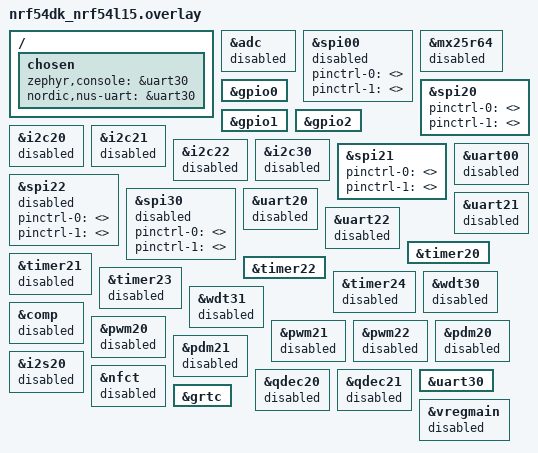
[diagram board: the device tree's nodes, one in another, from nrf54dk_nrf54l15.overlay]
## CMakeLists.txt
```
cmake_minimum_required(VERSION 3.20.0)
find_package(Zephyr REQUIRED HINTS $ENV{ZEPHYR_BASE})

project(ADC_2)

target_sources(app PRIVATE
  src/main.c
  src/BLE.c
  src/data.c
  src/rtc_stim.c
  src/spi.c
  src/timer.c
  src/ADC.c
)

if(CONFIG_BT)
  target_sources(app PRIVATE src/ble_session.c)
endif()
```

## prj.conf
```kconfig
#
# Copyright (c) 2024 Nordic Semiconductor
#
# SPDX-License-Identifier: LicenseRef-Nordic-5-Clause
#
CONFIG_BT=y
CONFIG_GPIO=y

#GATT
#CONFIG_BT_GATT_DYNAMIC_DB=names
CONFIG_BT_L2CAP_TX_BUF_COUNT=8
CONFIG_BT_BUF_ACL_TX_SIZE=251
CONFIG_BT_BUF_ACL_RX_SIZE=251
CONFIG_BT_CTLR_DATA_LENGTH_MAX=251
# STEP 1 - Enable nrfx drivers #
# Right names for low-level peripheral drivers
#CONFIG_ADC=y
CONFIG_NRFX_SAADC=y
CONFIG_NRFX_TIMER=y
CONFIG_NRFX_GPPI=y
# enable spi and other???
#CONFIG_CBPRINTF_FP_SUPPORT=y
#CONFIG_RESET_ON_FATAL_ERROR=n
#CONFIG_HEAP_MEM_POOL_SIZE=8192
#CONFIG_SYSTEM_WORKQUEUE_STACK_SIZE=2048
#CONFIG_MAIN_STACK_SIZE=4096
#CONFIG_THREAD_NAME=y
#CONFIG_BT_RX_STACK_SIZE=2048
# STEP 1.1 - Enable Kconfigs for SPI and GPIO
#CONFIG_GPIO=y
#CONFIG_SPI=y
##############################################################################
# BLE ON/OFF — set to n for RTC-only low-power stim (no radio)
##############################################################################

CONFIG_BT_PERIPHERAL=y
CONFIG_BT_DEVICE_NAME="Chronos"
CONFIG_BT_MAX_CONN=1
CONFIG_BT_NUS=y
#help buffers not to be dropped
CONFIG_BT_PERIPHERAL_PREF_MIN_INT=6
CONFIG_BT_PERIPHERAL_PREF_MAX_INT=6
CONFIG_BT_PERIPHERAL_PREF_LATENCY=0
CONFIG_BT_PERIPHERAL_PREF_TIMEOUT=400
#CONFIG_BT_NUS_SECURITY_ENABLED=n

##############################################################################
# Peripherals: GPIO, SPIM1, TIMER0 (burst), TIMER2 (period)
##############################################################################
#CONFIG_NRFX=y
CONFIG_DEVICE_DT_METADATA=n
CONFIG_DEVICE_DEPS=n
CONFIG_NRFX_SPIM=y
CONFIG_NRFX_TIMER=y
CONFIG_GPIO=y
#CONFIG_SPI=y
#CONFIG_NRFX_SPIM00=y
CONFIG_NRFX_QSPI=n
# TIMER: nRF54L15 uses TIMER20, TIMER22 etc. (enable per-instance in overlay if needed)
#CONFIG_NRFX_TIMER0=y
#CONFIG_NRFX_TIMER1=y

##############################################################################
# DK LEDs (BLE build uses dk_set_led in main)
##############################################################################
CONFIG_DK_LIBRARY=y

##############################################################################
# Heap / stacks (BLE needs more than RTC-only)
##############################################################################
CONFIG_HEAP_MEM_POOL_SIZE=8192
CONFIG_SYSTEM_WORKQUEUE_STACK_SIZE=2048
CONFIG_MAIN_STACK_SIZE=2048
CONFIG_BT_RX_STACK_SIZE=2048

##############################################################################
# UART / serial (NUS UART + console)
# NUS sample path expects async UART; enables CONFIG_BT_NUS_UART_* sizes in Kconfig.
##############################################################################
CONFIG_SERIAL=y
CONFIG_UART_ASYNC_API=y

##############################################################################
# Console / log / debug
##############################################################################
CONFIG_CONSOLE=y
CONFIG_UART_CONSOLE=y
CONFIG_PRINTK=y
CONFIG_USE_SEGGER_RTT=n
CONFIG_LOG=y
CONFIG_LOG_DEFAULT_LEVEL=2
CONFIG_DEBUG_THREAD_INFO=n
CONFIG_ASSERT=n

##############################################################################
# Boot / size
##############################################################################
CONFIG_BOOT_BANNER=n
CONFIG_NCS_BOOT_BANNER=n
CONFIG_SIZE_OPTIMIZATIONS=y

##############################################################################
# Flash
##############################################################################
CONFIG_FLASH=y
CONFIG_FLASH_MAP=n
CONFIG_FLASH_PAGE_LAYOUT=n
CONFIG_SPI_NOR=n
```

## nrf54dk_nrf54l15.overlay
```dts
&adc {
    status = "disabled";
};
/*
 * Copyright (c) 2024 Nordic Semiconductor ASA
 *
 * SPDX-License-Identifier: LicenseRef-Nordic-5-Clause
 */
/*
 * nRF54L15: SPIM20 on P1 (nrfx). SCK P1.05, MOSI P1.06, CS1 P1.09, CS2 P1.14.
 * UART20 disabled so P1.x available. nrfx configures GPIO+PSEL; no pinctrl for SPI.
 */

/* Disabled: nrfx uses SPIM21; keep mx25r64 disabled to avoid spi00 bus reference. */
&spi00 {
	status = "disabled";
	pinctrl-0 = <>;
	pinctrl-1 = <>;
	pinctrl-names = "default", "sleep";
};
&mx25r64 {
	status = "disabled";
};
/* status = "okay" so SoC domain/clock for SPIM20 is enabled; nrfx drives SPI, no Zephyr SPI driver. */
&spi20 {
	status = "okay";
	pinctrl-0 = <>;
	pinctrl-1 = <>;
	pinctrl-names = "default", "sleep";
};

/* Still need to release NFC pins for GPIO use */
&gpio0 {
	status = "okay";
};
&gpio1 {
	status = "okay";
};
&gpio2 {
	status = "okay";
};
/* MBOX (IPC hardware) must be okay for BLE-over-IPC; fixes __device_dts_ord_25 undeclared. */
//&mbox {
	//status = "okay";
//};

/*
 * Power: explicitly disable unused peripherals so they are not initialized
 * (no clocks, no power to those blocks). App uses: uart30, spi20 (nrfx SPIM20), timer00/10 (nrfx), gpio, flash, mbox.
 * nRF54L15 labels: i2c20/21/22/30, spi00/20/21/22/30, uart00/20/21/22/30, timer20/21/22/23/24, etc.
 */
&i2c20 { status = "disabled"; };
&i2c21 { status = "disabled"; };
&i2c22 { status = "disabled"; };
&i2c30 { status = "disabled"; };
/* spi00/spi20 cleared above for nrfx; clear pinctrl on rest to avoid device ord refs. */
&spi21 {
	status = "okay";
	pinctrl-0 = <>;
	pinctrl-1 = <>;
	pinctrl-names = "default", "sleep";
};
&spi22 {
	status = "disabled";
	pinctrl-0 = <>;
	pinctrl-1 = <>;
	pinctrl-names = "default", "sleep";
};
&spi30 {
	status = "disabled";
	pinctrl-0 = <>;
	pinctrl-1 = <>;
	pinctrl-names = "default", "sleep";
};
&uart00 { status = "disabled"; };
&uart20 { status = "disabled"; };
&uart21 { status = "disabled"; };
&uart22 { status = "disabled"; };
&adc { status = "disabled"; };
&timer20 { status = "okay"; };
&timer21 { status = "disabled"; };
&timer22 { status = "okay"; };
&timer23 { status = "disabled"; };
&timer24 { status = "disabled"; };
&wdt30 { status = "disabled"; };
&wdt31 { status = "disabled"; };
&comp { status = "disabled"; };
&pwm20 { status = "disabled"; };
&pwm21 { status = "disabled"; };
&pwm22 { status = "disabled"; };
&pdm20 { status = "disabled"; };
&pdm21 { status = "disabled"; };
&i2s20 { status = "disabled"; };
&nfct { status = "disabled"; };
&qdec20 { status = "disabled"; };
&qdec21 { status = "disabled"; };

/* LFXO: reverted - disabling it increased power on this design. Leave default. */
/* &lfxo { status = "disabled"; }; */
/ {
	chosen {
		zephyr,console = &uart30;
		nordic,nus-uart = &uart30;
	};
};

/* nRF54L15 DK uses UART30 for NUS; ensure it is enabled. */
&uart30 {
	status = "okay";
};
&grtc {
    status = "okay";
};
&vregmain {
    status = "disabled";
};
```

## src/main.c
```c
/*
Author: Brandon S Coventry      Wisconsin Institute for Translational Neuroengineering
Date: 2026/02/12 Initialization
Purpose: Chronos firmware ported for the nRF54L15
Revision History: See Github history
Notes:
 - Includes the ability to turn bluetooth transmission on and off in config file. Set CONFIG_BT in config file to 0 to turn off BLE engine
 - Primary stimulation driver is still and interupt based routine. 
*/

/*Basic includes. Minimize to limit current draw from unused engines.*/
//Zephyr includes
#include <zephyr/kernel.h>
#include <zephyr/types.h>
#include <zephyr/irq.h> //Interrupt service routine handlers
#include <zephyr/device.h>  //Must import devicetree files
#include <zephyr/devicetree.h>
#include <soc.h>    //Standard System on chip imports
#include <zephyr/logging/log.h>   //Disable on compile
#include <inttypes.h>

#if defined(CONFIG_BT)
#include <zephyr/bluetooth/bluetooth.h>
#include <zephyr/bluetooth/conn.h>
#endif

//nRFX imports. Note we are primarily runnig
#include <nrfx_spim.h>
#include <nrfx_timer.h>
#include <zephyr/sys/atomic.h>
#include <hal/nrf_gpio.h>
#include <hal/nrf_clock.h>
#if defined(CONFIG_NRFX_SAADC)
#include <nrfx_saadc.h>
#include <helpers/nrfx_gppi.h>
#endif
#if defined(CONFIG_SPI)
#include <zephyr/drivers/spi.h>
#endif

//Chronos engine imports 
#include "BLE.h"  //BLE engine
#include "ble_session.h"
#include "spi.h" //SPI to howland current source
#include "timer.h"  //Handles interrupt timing of stimulation
#include "rtc_stim.h"   //handles IRQ routines for stimulation
#include "data.h"
#include "config.h"   //Set compilation settings. Look here for CONFIG_BT
#include "ADC.h"

#define LOG_MODULE_NAME main
LOG_MODULE_REGISTER(LOG_MODULE_NAME, LOG_LEVEL_INF);

//Add UART Driver only if BLE is active. Note, UART is *virtual*, but still requires pin definitions. 
#if defined(CONFIG_BT)
#include <uart_async_adapter.h>
#include <zephyr/drivers/uart.h>
#include <zephyr/usb/usb_device.h>
#endif

//Set up peripherial initialization
static void init_clock();   //Turn on stimulation timing engine
#if defined(CONFIG_BT)
BT_CONN_CB_DEFINE(conn_callbacks) = {
	.connected        = connected,
	.disconnected     = disconnected,
	.recycled         = recycled_cb,
#ifdef CONFIG_BT_NUS_SECURITY_ENABLED
	.security_changed = security_changed,
#endif
};
#endif /* CONFIG_BT */

static void init_pins(void) {
    /* SPI CS and switches are GPIO. When CONFIG_SPI=y the Zephyr driver owns DAC1_CS (P1.08 in Zephyr devicetree). */
#if !defined(CONFIG_SPI)
    nrf_gpio_cfg_output(DAC1_CS_PIN);
    nrf_gpio_pin_set(DAC1_CS_PIN);   /* high (inactive) */
#endif
    nrf_gpio_cfg_output(DAC2_CS_PIN);
    nrf_gpio_pin_set(DAC2_CS_PIN);   /* high (inactive) */
    
    // Switch GPIOs (DAC1/2 -> switch): all 0 at init (merged 0.02/0.03 line)
    nrf_gpio_cfg_output(NRF_GPIO_PIN_MAP(1, 13));
    nrf_gpio_pin_clear(NRF_GPIO_PIN_MAP(1, 13));
    nrf_gpio_cfg_output(NRF_GPIO_PIN_MAP(1, 7));
    nrf_gpio_pin_clear(NRF_GPIO_PIN_MAP(1, 7));
    nrf_gpio_cfg_output(NRF_GPIO_PIN_MAP(1, 5));
    nrf_gpio_pin_clear(NRF_GPIO_PIN_MAP(1, 5));
}

int main(void)
{
    //Begin with system initialization




#if defined(CONFIG_BT)
    init_clock();
#endif
    init_pins();
#if defined(CONFIG_SPI)
    /* Zephyr SPI test build: no nrfx SPI/timer activity here. */
    k_msleep(10);
#else
    /* nrfx build: initialize SPI once; transactions are driven from timer ISR. */
    spi_init();
#endif
#if defined(CONFIG_BT)
    timer_init();
#else
    timer_burst_init();
#endif
    update_pulse_width(CONFIG_PULSE_WIDTH_US);
    update_dac1_amplitude(CONFIG_STIM_AMPLITUDE);
    update_dac2_amplitude(CONFIG_STIM_AMPLITUDE);

    data_init_defaults();

#if defined(CONFIG_BT)
	/* Stimulation timer stays off until START control byte (see data.c). */
	measurement_timer_init();
	int err = 0;
	uint32_t experiment_counter = 0;

	configure_gpio();
	err = uart_init();
	if (err) {
		error();
	}

	if (IS_ENABLED(CONFIG_BT_NUS_SECURITY_ENABLED)) {
		err = bt_conn_auth_cb_register(&conn_auth_callbacks);
		if (err) {
			LOG_ERR("Failed to register authorization callbacks. (err: %d)", err);
			return 0;
		}

		err = bt_conn_auth_info_cb_register(&conn_auth_info_callbacks);
		if (err) {
			LOG_ERR("Failed to register authorization info callbacks. (err: %d)", err);
			return 0;
		}
	}

	ble_session_init();
	LOG_INF("Toggle reed P1.10 to enable BLE; stimulation off until START byte");


	/* RUN_STATUS_LED is driven by ble_session (on while BLE session active). */
	for (;;) {
		if (MEASURE_TIMER == 1) {
			k_msleep(10000);
			experiment_counter += 10;
			error_data my_error_data;
			get_error_data(&my_error_data);
			printf("Counter: %i Elapsed: %is\nEvent0 running error: %" PRIu32
			       " avg error: %" PRIu32 " max error: %" PRIu32 "\n"
			       "Events1-3 running error: %" PRIu32 " avg error: %" PRIu32
			       " max error: %" PRIu32 ", %" PRIu32 ", %" PRIu32 "\n",
			       my_error_data.mycounter,
			       experiment_counter,
			       my_error_data.event0_error,
			       (my_error_data.event0_error / my_error_data.mycounter),
			       my_error_data.event0_max,
			       my_error_data.myerror,
			       (my_error_data.myerror / my_error_data.mycounter),
			       my_error_data.event1_max,
			       my_error_data.event2_max,
			       my_error_data.event3_max);
		} else {
			k_sleep(K_FOREVER);
		}
	}
    #else
        /* RTC low-power: no BLE; RTC wakes every stim period, timer runs one biphasic burst */
        rtc_stim_start_lfclk();
        rtc_stim_init(CONFIG_STIM_FREQUENCY_HZ);
        LOG_INF("RTC-driven stimulation at %u Hz (no BLE)", CONFIG_STIM_FREQUENCY_HZ);
        for (;;) {
            k_sleep(K_FOREVER);
        }
    #endif /* CONFIG_BT */


    }

    K_THREAD_DEFINE(ble_write_thread_id, STACKSIZE, ble_write_thread, NULL, NULL,
            NULL, PRIORITY, 0, 0);

    static void init_clock() {
#if !defined(CONFIG_SOC_NRF54L15)
        nrf_clock_hfclk_src_set(NRF_CLOCK_S, NRF_CLOCK_HFCLK_HIGH_ACCURACY);
#endif
        nrf_clock_task_trigger(NRF_CLOCK_S, NRF_CLOCK_TASK_HFCLKSTART);
        while (!nrf_clock_event_check(NRF_CLOCK_S, NRF_CLOCK_EVENT_HFCLKSTARTED)) {
            /* spin */
        }
        nrf_clock_event_clear(NRF_CLOCK_S, NRF_CLOCK_EVENT_HFCLKSTARTED);
    }
```

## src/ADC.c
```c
#include <zephyr/kernel.h>
#include <zephyr/logging/log.h>

LOG_MODULE_REGISTER(Chronos_adc, LOG_LEVEL_DBG);

/* STEP 2 - Include header for nrfx drivers */
#include <nrfx_saadc.h>
#include <nrfx_timer.h>
#include <helpers/nrfx_gppi.h>
// Include headers for zephyr SPI driver//
#include <zephyr/logging/log.h>
#include <zephyr/device.h>
#include <zephyr/devicetree.h>
#include <zephyr/drivers/gpio.h>
#include "BLE.h"
#include "ADC.h"





//#define SAADC_INPUT_PIN2 NRFX_ANALOG_EXTERNAL_AIN2
static nrfx_saadc_channel_t channel1 = NRFX_SAADC_DEFAULT_CHANNEL_SE(SAADC_INPUT_PIN1, 0);
//static nrfx_saadc_channel_t channel2 = NRFX_SAADC_DEFAULT_CHANNEL_SE(SAADC_INPUT_PIN2, 0);
//Define the SPI INIT
//SPI worc set changed to 16, see what happens, change back to 8 if not helpful
/* STEP 3.2 - Declaring an instance of nrfx_timer for TIMER2. */
nrfx_timer_t timer_instance = NRFX_TIMER_INSTANCE(TIMER_INSTANCE_NUMBER);
//New added up here hmmmmmm lets see
/* STEP 4.2 - Declare the buffers for the SAADC */
static int16_t saadc_sample_buffer[8][SAADC_BUFFER_SIZE];
//establishing a message queue for SAADC filled buffer pointers
K_MSGQ_DEFINE(ble_msgq, sizeof(int16_t *), 8, 4);
//Begins the spi thread of communication//
static void ble_thread(void *a, void *b, void *c) {
    k_sem_take(&ble_init_ok, K_FOREVER);
    int16_t *buf;
    while (1) {
        k_msgq_get(&ble_msgq, &buf, K_FOREVER);
        if (!current_conn) {
            continue;
        }
        ble_send_samples(buf, SAADC_BUFFER_SIZE);
        LOG_INF("Sample sent succesfully!");
    }
}
K_THREAD_DEFINE(ble_tid, 4096, ble_thread, NULL, NULL, NULL, 3, 0, 0);

/* STEP 4.3 - Declare variable used to keep track of which buffer was last assigned to the SAADC driver */
static uint32_t saadc_current_buffer = 2;

/*functions to control adc recording and stopping*/
static bool adc_active = false;
bool adc_recording_is_active(void) {
    return adc_active;
}
void adc_recording_start(void) {
    if (adc_active) {
        LOG_INF("SAADC already running");
        return;
    }
    configure_timer();
    configure_saadc();
    configure_ppi();
    adc_active=true;
    LOG_INF("SAADC recording started");
}
void adc_recording_stop(void) {
    if (!adc_active) {
        LOG_INF("SAADC already stopped");
        return;
    }
    nrfx_timer_disable(&timer_instance);
    nrfx_timer_uninit(&timer_instance);
    nrfx_saadc_uninit();
    saadc_current_buffer = 2;
    adc_active = false;
    LOG_INF("SAADC recording stopped");
}


void configure_timer(void)
{
    nrfx_err_t err;

    /* STEP 3.3 - Declaring timer config and intialize nrfx_timer instance. */
    nrfx_timer_config_t timer_config = NRFX_TIMER_DEFAULT_CONFIG(1000000);
    err = nrfx_timer_init(&timer_instance, &timer_config, NULL);
    if (err !=0) {
        LOG_ERR("nrfx_timer_init error: %08x", err);
        return;
    }

    /* STEP 3.4 - Set compare channel 0 to generate event every SAADC_SAMPLE_INTERVAL_US. */
    uint32_t timer_ticks = nrfx_timer_us_to_ticks(&timer_instance, SAADC_SAMPLE_INTERVAL_US);
    nrfx_timer_extended_compare(&timer_instance, NRF_TIMER_CC_CHANNEL0, timer_ticks, NRF_TIMER_SHORT_COMPARE0_CLEAR_MASK, false);
    LOG_INF("nrfx timer22 configured successfully");

}

static void saadc_event_handler(nrfx_saadc_evt_t const * p_event)
{
    nrfx_err_t err;
    switch (p_event->type)
    {

        case NRFX_SAADC_EVT_READY:
        
           /* STEP 5.1 - Buffer is ready, timer (and sampling) can be started. */
           nrfx_timer_enable(&timer_instance);

            break;                        
            
       case NRFX_SAADC_EVT_BUF_REQ:
        uint32_t next = saadc_current_buffer % 8;
           err = nrfx_saadc_buffer_set(saadc_sample_buffer[next], SAADC_BUFFER_SIZE);
            if (err != 0) {
            LOG_ERR("nrfx_saadc_buffer_set error: %08x  init", err);
            return;
            }
            saadc_current_buffer++;
            break;
         //   uint32_t next = saadc_current_buffer % 4;
           // err = nrfx_saadc_buffer_set(saadc_sample_buffer[next], SAADC_BUFFER_SIZE);
            //if (err != 0) {
            //LOG_ERR("nrfx_saadc_buffer_set error: %08x", err);
            //return;
            //}
            //saadc_current_buffer++;
        
            /* STEP 5.2 - Set up the next available buffer. Alternate through buffers 0-4 */
           
            

           // err = nrfx_saadc_buffer_set(saadc_sample_buffer[(saadc_current_buffer++)%4], SAADC_BUFFER_SIZE);
            //if (err != 0) {
              //  LOG_ERR("nrfx_saadc_buffer_set error: %08x", err);
                //return;
            //}

            //break;

        case NRFX_SAADC_EVT_DONE:
           

           // err = nrfx_saadc_buffer_set(saadc_sample_buffer[next], SAADC_BUFFER_SIZE);
            //if (err != 0) {
            //LOG_ERR("nrfx_saadc_buffer_set error: %08x init", err);
            //return;
            //}
           // saadc_current_buffer++;
         /* STEP 5.3 - Buffer has been filled. Do something with the data and proceed */
          /*  int64_t average = 0;
            int16_t max = INT16_MIN;
            int16_t min = INT16_MAX;
            int16_t current_value; 
            for(int i=0; i < p_event->data.done.size; i++){
                current_value = ((int16_t *)(p_event->data.done.p_buffer))[i];
                average += current_value;
                if(current_value > max){
                    max = current_value;
                }
                if(current_value < min){
                    min = current_value;
                }
            }
            average = average/p_event->data.done.size;
            LOG_INF("SAADC buffer at 0x%x filled with %d samples", (uint32_t)p_event->data.done.p_buffer, p_event->data.done.size);
            LOG_INF("AVG=%d, MIN=%d, MAX=%d", (int16_t)average, min, max);
            break;*/
        //default:
          //  LOG_INF("Unhandled SAADC evt %d", p_event->type);
           // break;

            /* STEP 5.3 - Buffer has been filled. Do something with the data and proceed */ //This will be changed to instead pass the buffer through SPI to fRAM//

         //  { int16_t *buf   = ((int16_t *)(p_event->data.done.p_buffer));
           // uint16_t count = (p_event->data.done.size);   /* number of int16_t samples */

           //  spi_send_samples(buf, count);

                /* Re-arm the same buffer for the next fill */
           // }
           //puts message of filled buffer pointer into queue
           int16_t *buf = p_event->data.done.p_buffer;
           int ret = k_msgq_put(&ble_msgq, &buf, K_NO_WAIT);
            if (ret != 0) {
            LOG_ERR("BLE msgq full! Buffer dropped at 0x%x", (uint32_t)buf);
            }
            

            break;
             default:
            LOG_INF("Unhandled SAADC evt %d", p_event->type);
            break;
        }     
       

}


void configure_saadc(void)
{
    nrfx_err_t err;

    /* STEP 4.4 - Connect ADC interrupt to nrfx interrupt handler */
    IRQ_CONNECT(DT_IRQN(DT_NODELABEL(adc)),
              DT_IRQ(DT_NODELABEL(adc), priority),
            nrfx_isr, nrfx_saadc_irq_handler, 0);
    /* STEP 4.5 - Initialize the nrfx_SAADC driver */
    err = nrfx_saadc_init(DT_IRQ(DT_NODELABEL(adc), priority));
    if (err!= 0) {
        LOG_ERR("nrfx_saadc_init error: %08x", err);
        return;
    }

    /* STEP 4.7 - Change gain config in default config and apply channel configuration */
    channel1.channel_config.gain = NRF_SAADC_GAIN1_4;
    channel1.channel_config.reference= NRF_SAADC_REFERENCE_INTERNAL;
    err = nrfx_saadc_channels_config(&channel1, 1);
    if (err != 0) {
        LOG_ERR("nrfx_saadc_channels_config error : %08x", err);
        return;
    }
    //channel2.channel_config.gain = NRF_SAADC_GAIN1_4;
    //channel2.channel_config.reference= NRF_SAADC_REFERENCE_INTERNAL;
    //err = nrfx_saadc_channels_config(&channel2, 1);
    //if (err != 0) {
      //  LOG_ERR("nrfx_saadc_channels_config error : %08x",err);
        //return;
    //}

    /* STEP 4.8 - Configure channel 0 in advanced mode with event handler (non-blocking mode) */

    nrfx_saadc_adv_config_t saadc_adv_config = NRFX_SAADC_DEFAULT_ADV_CONFIG;
    err = nrfx_saadc_advanced_mode_set(BIT(0),
                                        NRF_SAADC_RESOLUTION_12BIT,
                                        &saadc_adv_config,
                                        saadc_event_handler);
    if (err != 0) {
        LOG_ERR("nrfx_saadc_advanced_mode_set error: %08x", err);
        return;
    }

    /* STEP 4.9 - Configure two buffers to make use of double-buffering feature of SAADC */
    err = nrfx_saadc_buffer_set(saadc_sample_buffer[0], SAADC_BUFFER_SIZE);
    if (err != 0) {
        LOG_ERR("nrfx_saadc_buffer_set error: %08x 1", err);
        return;
    }
    err = nrfx_saadc_buffer_set(saadc_sample_buffer[1], SAADC_BUFFER_SIZE);
    if (err != 0) {
        LOG_ERR("nrfx_saadc_buffer_set error: %08x 2", err);
        return;
        LOG_INF("nrfx saadc configured successfully");
    }
   // err = nrfx_saadc_buffer_set(saadc_sample_buffer[2], SAADC_BUFFER_SIZE);
    //if (err != 0) {
      //  LOG_ERR("nrfx_saadc_buffer_set error: %08x 3", err);
        //return;
    //}
    //err = nrfx_saadc_buffer_set(saadc_sample_buffer[3], SAADC_BUFFER_SIZE);
    //if (err != 0) {
      //  LOG_ERR("nrfx_saadc_buffer_set error: %08x 4", err);
        //return;
    //}

    /* STEP 4.10 - Trigger the SAADC. This will not start sampling, but will prepare buffer for sampling triggered through PPI */
    err = nrfx_saadc_mode_trigger();
    if (err != 0) {
        LOG_ERR("nrfx_saadc_mode_trigger error: %08x", err);
        return;
    }

}

void configure_ppi(void)
{
    nrfx_err_t err;
    /* STEP 6.1 - Declare variables used to hold the (D)PPI channel number */
    nrfx_gppi_handle_t gppi_handle_sample;
    nrfx_gppi_handle_t gppi_handle_start;

    /* STEP 6.2 - Trigger task sample from timer */
    err = nrfx_gppi_conn_alloc( nrfx_timer_compare_event_address_get(&timer_instance, NRF_TIMER_CC_CHANNEL0),
                                nrf_saadc_task_address_get(NRF_SAADC, NRF_SAADC_TASK_SAMPLE), &gppi_handle_sample);
       if (err != 0) {
        LOG_ERR("nrfx_gppi_conn_alloc error: %08x", err);
        return;
       }                        
    /* STEP 6.3 - Trigger task start from end event */
    err = nrfx_gppi_conn_alloc(nrf_saadc_event_address_get(NRF_SAADC, NRF_SAADC_EVENT_END),
                                nrf_saadc_task_address_get(NRF_SAADC, NRF_SAADC_TASK_START), &gppi_handle_start);
    if (err != 0) {
        LOG_ERR("nrfx_gppi_conn_alloc error: %08x", err);
        return;
    } 
    /* STEP 6.4 - Enable both (D)PPI channels */ 
    nrfx_gppi_conn_enable(gppi_handle_sample);
nrfx_gppi_conn_enable(gppi_handle_start);
}
```

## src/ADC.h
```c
#ifndef ADC_H
#define ADC_H
#endif
#include <zephyr/device.h>
#include <zephyr/devicetree.h>
#include <zephyr/kernel.h>

#if defined(CONFIG_NRFX_SAADC)
#include <nrfx_saadc.h>
#endif
#define SAADC_SAMPLE_INTERVAL_US 500
#define SAADC_BUFFER_SIZE 8
#define SAADC_INPUT_PIN1 NRFX_ANALOG_EXTERNAL_AIN5
#define TIMER_INSTANCE_NUMBER NRF_TIMER22
void configure_timer(void);
void configure_saadc(void);
void configure_ppi(void);
void adc_recording_start(void);
void adc_recording_stop(void);
bool adc_recording_is_active(void);
```

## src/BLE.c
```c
#if defined(CONFIG_BT)
#include <uart_async_adapter.h>
#include <zephyr/drivers/uart.h>
#include <zephyr/usb/usb_device.h>
#include <dk_buttons_and_leds.h>
#endif

#include <zephyr/types.h>
#include <zephyr/kernel.h>
#include <zephyr/device.h>
#include <zephyr/devicetree.h>
#include <soc.h>
#if defined(CONFIG_BT)
#include <zephyr/bluetooth/bluetooth.h>
#include <zephyr/bluetooth/uuid.h>
#include <zephyr/bluetooth/gatt.h>
#include <zephyr/bluetooth/hci.h>
#include <bluetooth/services/nus.h>
#include <zephyr/settings/settings.h>
#endif

#include <stdio.h>
#include <string.h>

#include <zephyr/logging/log.h>
#define LOG_MODULE_NAME peripheral_uart
#include "BLE.h"
#include "ble_session.h"
#include "data.h"

LOG_MODULE_REGISTER(LOG_MODULE_NAME);
K_SEM_DEFINE(ble_init_ok, 0, 1);

#if defined(CONFIG_BT)
const struct device *uart = DEVICE_DT_GET(DT_CHOSEN(nordic_nus_uart));
struct k_work_delayable uart_work;
static K_FIFO_DEFINE(fifo_uart_tx_data);
static K_FIFO_DEFINE(fifo_uart_rx_data);
#endif

#if defined(CONFIG_BT)
const struct bt_data ad[] = {
	BT_DATA_BYTES(BT_DATA_FLAGS, (BT_LE_AD_GENERAL | BT_LE_AD_NO_BREDR)),
	BT_DATA(BT_DATA_NAME_COMPLETE, DEVICE_NAME, DEVICE_NAME_LEN),
};
const size_t ad_len = ARRAY_SIZE(ad);
const struct bt_data sd[] = {
	BT_DATA_BYTES(BT_DATA_UUID128_ALL, BT_UUID_NUS_VAL),
};
const size_t sd_len = ARRAY_SIZE(sd);
struct k_work adv_work;
struct bt_conn *current_conn;
struct bt_conn *auth_conn;
bool ble_data_ready = false;
#endif

#if defined(CONFIG_BT)
void uart_work_handler(struct k_work *item)
{
	struct uart_data_t *buf;

	buf = k_malloc(sizeof(*buf));
	if (buf) {
		buf->len = 0;
	} else {
		LOG_WRN("Not able to allocate UART receive buffer");
		k_work_reschedule(&uart_work, UART_WAIT_FOR_BUF_DELAY);
		return;
	}

	uart_rx_enable(uart, buf->data, sizeof(buf->data), UART_WAIT_FOR_RX);
}

bool uart_test_async_api(const struct device *dev)
{
#if defined(CONFIG_UART_ASYNC_API)
	const struct uart_driver_api *api =
		(const struct uart_driver_api *)dev->api;

	return (api->callback_set != NULL);
#else
	ARG_UNUSED(dev);
	return false;
#endif
}
#endif

#if defined(CONFIG_BT)
void adv_work_handler(struct k_work *work)
{
	int err = bt_le_adv_start(BT_LE_ADV_CONN_FAST_2, ad, ad_len, sd, sd_len);

	if (err) {
		LOG_ERR("Advertising failed to start (err %d)", err);
		return;
	}

	LOG_INF("Advertising successfully started");
}

void advertising_start(void)
{
	k_work_submit(&adv_work);
}

void connected(struct bt_conn *conn, uint8_t err)
{
	char addr[BT_ADDR_LE_STR_LEN];

	if (err) {
		LOG_ERR("Connection failed, err 0x%02x %s", err, bt_hci_err_to_str(err));
		return;
	}

	bt_addr_le_to_str(bt_conn_get_dst(conn), addr, sizeof(addr));

	LOG_INF("Connected %s", addr);

	current_conn = bt_conn_ref(conn);

	dk_set_led_on(CON_STATUS_LED);

}

void disconnected(struct bt_conn *conn, uint8_t reason)
{
	char addr[BT_ADDR_LE_STR_LEN];

	bt_addr_le_to_str(bt_conn_get_dst(conn), addr, sizeof(addr));

	LOG_INF("Disconnected: %s, reason 0x%02x %s", addr, reason, bt_hci_err_to_str(reason));

	if (auth_conn) {
		bt_conn_unref(auth_conn);
		auth_conn = NULL;
	}

	if (current_conn) {
		bt_conn_unref(current_conn);
		current_conn = NULL;
		dk_set_led_off(CON_STATUS_LED);
	}
}

void recycled_cb(void)
{
	LOG_INF("Connection object available from previous conn. Disconnect is complete!");
	advertising_start();
}

#ifdef CONFIG_BT_NUS_SECURITY_ENABLED
void security_changed(struct bt_conn *conn, bt_security_t level,
			     enum bt_security_err err)
{
	char addr[BT_ADDR_LE_STR_LEN];

	bt_addr_le_to_str(bt_conn_get_dst(conn), addr, sizeof(addr));

	if (!err) {
		LOG_INF("Security changed: %s level %u", addr, level);
	} else {
		LOG_WRN("Security failed: %s level %u err %d %s", addr, level, err,
			bt_security_err_to_str(err));
	}
}
#endif /* CONFIG_BT_NUS_SECURITY_ENABLED */

#if defined(CONFIG_BT_NUS_SECURITY_ENABLED)
void auth_passkey_display(struct bt_conn *conn, unsigned int passkey)
{
	char addr[BT_ADDR_LE_STR_LEN];

	bt_addr_le_to_str(bt_conn_get_dst(conn), addr, sizeof(addr));

	LOG_INF("Passkey for %s: %06u", addr, passkey);
}

void auth_passkey_confirm(struct bt_conn *conn, unsigned int passkey)
{
	char addr[BT_ADDR_LE_STR_LEN];

	auth_conn = bt_conn_ref(conn);

	bt_addr_le_to_str(bt_conn_get_dst(conn), addr, sizeof(addr));

	LOG_INF("Passkey for %s: %06u", addr, passkey);

	if (IS_ENABLED(CONFIG_SOC_SERIES_NRF54HX) || IS_ENABLED(CONFIG_SOC_SERIES_NRF54LX)) {
		LOG_INF("Press Button 0 to confirm, Button 1 to reject.");
	} else {
		LOG_INF("Press Button 1 to confirm, Button 2 to reject.");
	}
}


void auth_cancel(struct bt_conn *conn)
{
	char addr[BT_ADDR_LE_STR_LEN];

	bt_addr_le_to_str(bt_conn_get_dst(conn), addr, sizeof(addr));

	LOG_INF("Pairing cancelled: %s", addr);
}


void pairing_complete(struct bt_conn *conn, bool bonded)
{
	char addr[BT_ADDR_LE_STR_LEN];

	bt_addr_le_to_str(bt_conn_get_dst(conn), addr, sizeof(addr));

	LOG_INF("Pairing completed: %s, bonded: %d", addr, bonded);
}


void pairing_failed(struct bt_conn *conn, enum bt_security_err reason)
{
	char addr[BT_ADDR_LE_STR_LEN];

	bt_addr_le_to_str(bt_conn_get_dst(conn), addr, sizeof(addr));

	LOG_INF("Pairing failed conn: %s, reason %d %s", addr, reason,
		bt_security_err_to_str(reason));
}

struct bt_conn_auth_cb conn_auth_callbacks = {
	.passkey_display = auth_passkey_display,
	.passkey_confirm = auth_passkey_confirm,
	.cancel = auth_cancel,
};

struct bt_conn_auth_info_cb conn_auth_info_callbacks = {
	.pairing_complete = pairing_complete,
	.pairing_failed = pairing_failed
};
#else
struct bt_conn_auth_cb conn_auth_callbacks;
struct bt_conn_auth_info_cb conn_auth_info_callbacks;
#endif /* CONFIG_BT_NUS_SECURITY_ENABLED */

#ifdef CONFIG_BT_NUS_SECURITY_ENABLED
void num_comp_reply(bool accept)
{
	if (accept) {
		bt_conn_auth_passkey_confirm(auth_conn);
		LOG_INF("Numeric Match, conn %p", (void *)auth_conn);
	} else {
		bt_conn_auth_cancel(auth_conn);
		LOG_INF("Numeric Reject, conn %p", (void *)auth_conn);
	}

	bt_conn_unref(auth_conn);
	auth_conn = NULL;
}

void button_changed(uint32_t button_state, uint32_t has_changed)
{
	uint32_t buttons = button_state & has_changed;

	if (auth_conn) {
		if (buttons & KEY_PASSKEY_ACCEPT) {
			num_comp_reply(true);
		}

		if (buttons & KEY_PASSKEY_REJECT) {
			num_comp_reply(false);
		}
	}
}
#endif /* CONFIG_BT_NUS_SECURITY_ENABLED */
#endif /* CONFIG_BT */

#if defined(CONFIG_BT)
void configure_gpio(void)
{
	int err;

#ifdef CONFIG_BT_NUS_SECURITY_ENABLED
	err = dk_buttons_init(button_changed);
	if (err) {
		LOG_ERR("Cannot init buttons (err: %d)", err);
	}
#endif /* CONFIG_BT_NUS_SECURITY_ENABLED */

	err = dk_leds_init();
	if (err) {
		LOG_ERR("Cannot init LEDs (err: %d)", err);
	}
}

void error(void)
{
	dk_set_leds_state(DK_ALL_LEDS_MSK, DK_NO_LEDS_MSK);

	while (true) {
		/* Spin for ever */
		k_sleep(K_MSEC(1000));
	}
}
#endif /* CONFIG_BT */

#if defined(CONFIG_BT)
void bt_receive_cb(struct bt_conn *conn, const uint8_t *const data,
			  uint16_t len)
{
	ble_session_feed_activity();

	if (len <= BLE_DATA_BUFFER_SIZE) {
		memcpy(ble_received_data, data, len);
		ble_data_length = len;
		ble_data_ready = true;
	}

	process_received_data(&settings, ble_received_data, ble_data_length);
}
int ble_send_samples(int16_t *samples, size_t count)
{
#if defined(CONFIG_BT)
    if (!current_conn) {
        LOG_WRN("ble_send_samples: no connection");
        return -ENOTCONN;
    }

    size_t byte_count = count * sizeof(int16_t);

    int err = bt_nus_send(current_conn, (uint8_t *)samples, byte_count);
    if (err == -EINVAL) {
        LOG_WRN("ble_send_samples: -EINVAL — notifications not enabled by peer "
                "or payload too large (%d bytes)", byte_count);
    } else if (err) {
        LOG_WRN("ble_send_samples failed: %d", err);
    }
    return err;
#else
    return -ENOTSUP;
#endif
}

struct bt_nus_cb nus_cb = {
	.received = bt_receive_cb,
};

void ble_advertising_work_init(void)
{
	k_work_init(&adv_work, adv_work_handler);
}
#endif /* CONFIG_BT */

#if defined(CONFIG_BT)
void uart_cb(const struct device *dev, struct uart_event *evt, void *user_data)
{
	ARG_UNUSED(dev);

	static size_t aborted_len;
	struct uart_data_t *buf;
	static uint8_t *aborted_buf;
	static bool disable_req;

	switch (evt->type) {
	case UART_TX_DONE:
		LOG_DBG("UART_TX_DONE");
		if ((evt->data.tx.len == 0) ||
		    (!evt->data.tx.buf)) {
			return;
		}

		if (aborted_buf) {
			buf = CONTAINER_OF(aborted_buf, struct uart_data_t,
					   data[0]);
			aborted_buf = NULL;
			aborted_len = 0;
		} else {
			buf = CONTAINER_OF(evt->data.tx.buf, struct uart_data_t,
					   data[0]);
		}

		k_free(buf);

		buf = k_fifo_get(&fifo_uart_tx_data, K_NO_WAIT);
		if (!buf) {
			return;
		}

		if (uart_tx(uart, buf->data, buf->len, SYS_FOREVER_MS)) {
			LOG_WRN("Failed to send data over UART");
		}

		break;

	case UART_RX_RDY:
		LOG_DBG("UART_RX_RDY");
		buf = CONTAINER_OF(evt->data.rx.buf, struct uart_data_t, data[0]);
		buf->len += evt->data.rx.len;

		if (disable_req) {
			return;
		}

		if ((evt->data.rx.buf[buf->len - 1] == '\n') ||
		    (evt->data.rx.buf[buf->len - 1] == '\r')) {
			disable_req = true;
			uart_rx_disable(uart);
		}

		break;

	case UART_RX_DISABLED:
		LOG_DBG("UART_RX_DISABLED");
		disable_req = false;

		buf = k_malloc(sizeof(*buf));
		if (buf) {
			buf->len = 0;
		} else {
			LOG_WRN("Not able to allocate UART receive buffer");
			k_work_reschedule(&uart_work, UART_WAIT_FOR_BUF_DELAY);
			return;
		}

		uart_rx_enable(uart, buf->data, sizeof(buf->data),
			       UART_WAIT_FOR_RX);

		break;

	case UART_RX_BUF_REQUEST:
		LOG_DBG("UART_RX_BUF_REQUEST");
		buf = k_malloc(sizeof(*buf));
		if (buf) {
			buf->len = 0;
			uart_rx_buf_rsp(uart, buf->data, sizeof(buf->data));
		} else {
			LOG_WRN("Not able to allocate UART receive buffer");
		}

		break;

	case UART_RX_BUF_RELEASED:
		LOG_DBG("UART_RX_BUF_RELEASED");
		buf = CONTAINER_OF(evt->data.rx_buf.buf, struct uart_data_t,
				   data[0]);

		if (buf->len > 0) {
			k_fifo_put(&fifo_uart_rx_data, buf);
		} else {
			k_free(buf);
		}

		break;

	case UART_TX_ABORTED:
		LOG_DBG("UART_TX_ABORTED");
		if (!aborted_buf) {
			aborted_buf = (uint8_t *)evt->data.tx.buf;
		}

		aborted_len += evt->data.tx.len;
		buf = CONTAINER_OF((void *)aborted_buf, struct uart_data_t,
				   data[0]);

		uart_tx(uart, &buf->data[aborted_len],
			buf->len - aborted_len, SYS_FOREVER_MS);

		break;

	default:
		break;
	}
}
#endif /* CONFIG_BT */

#if defined(CONFIG_BT)
int uart_init(void)
{
	int err;
	int pos;
	struct uart_data_t *rx;
	struct uart_data_t *tx;

	if (!device_is_ready(uart)) {
		return -ENODEV;
	}

	if (IS_ENABLED(CONFIG_USB_DEVICE_STACK)) {
		err = usb_enable(NULL);
		if (err && (err != -EALREADY)) {
			LOG_ERR("Failed to enable USB");
			return err;
		}
	}

	rx = k_malloc(sizeof(*rx));
	if (rx) {
		rx->len = 0;
	} else {
		return -ENOMEM;
	}

	k_work_init_delayable(&uart_work, uart_work_handler);


	if (IS_ENABLED(CONFIG_UART_ASYNC_ADAPTER) && !uart_test_async_api(uart)) {
		/* Implement API adapter */
		uart_async_adapter_init(async_adapter, uart);
		uart = async_adapter;
	}

	err = uart_callback_set(uart, uart_cb, NULL);
	if (err) {
		k_free(rx);
		LOG_ERR("Cannot initialize UART callback");
		return err;
	}

	if (IS_ENABLED(CONFIG_UART_LINE_CTRL)) {
		LOG_INF("Wait for DTR");
		while (true) {
			uint32_t dtr = 0;

			uart_line_ctrl_get(uart, UART_LINE_CTRL_DTR, &dtr);
			if (dtr) {
				break;
			}
			/* Give CPU resources to low priority threads. */
			k_sleep(K_MSEC(100));
		}
		LOG_INF("DTR set");
		err = uart_line_ctrl_set(uart, UART_LINE_CTRL_DCD, 1);
		if (err) {
			LOG_WRN("Failed to set DCD, ret code %d", err);
		}
		err = uart_line_ctrl_set(uart, UART_LINE_CTRL_DSR, 1);
		if (err) {
			LOG_WRN("Failed to set DSR, ret code %d", err);
		}
	}

	tx = k_malloc(sizeof(*tx));

	if (tx) {
		pos = snprintf(tx->data, sizeof(tx->data),
			       "Starting Nordic UART service sample\r\n");

		if ((pos < 0) || (pos >= sizeof(tx->data))) {
			k_free(rx);
			k_free(tx);
			LOG_ERR("snprintf returned %d", pos);
			return -ENOMEM;
		}

		tx->len = pos;
	} else {
		k_free(rx);
		return -ENOMEM;
	}

	err = uart_tx(uart, tx->data, tx->len, SYS_FOREVER_MS);
	if (err) {
		k_free(rx);
		k_free(tx);
		LOG_ERR("Cannot display welcome message (err: %d)", err);
		return err;
	}

	err = uart_rx_enable(uart, rx->data, sizeof(rx->data), UART_WAIT_FOR_RX);
	if (err) {
		LOG_ERR("Cannot enable uart reception (err: %d)", err);
		/* Free the rx buffer only because the tx buffer will be handled in the callback */
		k_free(rx);
	}

	return err;
}
#endif /* CONFIG_BT */

void ble_write_thread(void)
{
#if defined(CONFIG_BT)
	/* Don't go any further until BLE is initialized */
	k_sem_take(&ble_init_ok, K_FOREVER);
	struct uart_data_t nus_data = {
		.len = 0,
	};

	for (;;) {
		/* Wait indefinitely for data to be sent over bluetooth */
		struct uart_data_t *buf = k_fifo_get(&fifo_uart_rx_data,
						     K_FOREVER);

		int plen = MIN(sizeof(nus_data.data) - nus_data.len, buf->len);
		int loc = 0;

		while (plen > 0) {
			memcpy(&nus_data.data[nus_data.len], &buf->data[loc], plen);
			nus_data.len += plen;
			loc += plen;

			if (nus_data.len >= sizeof(nus_data.data) ||
			   (nus_data.data[nus_data.len - 1] == '\n') ||
			   (nus_data.data[nus_data.len - 1] == '\r')) {
				if (bt_nus_send(NULL, nus_data.data, nus_data.len)) {
					LOG_WRN("Failed to send data over BLE connection");
				}
				nus_data.len = 0;
			}

			plen = MIN(sizeof(nus_data.data), buf->len - loc);
		}

		k_free(buf);
	}
#else
	/* BLE disabled: block thread so it never runs */
	k_sem_take(&ble_init_ok, K_FOREVER);
	for (;;) {
		k_sleep(K_FOREVER);
	}
#endif
}
```

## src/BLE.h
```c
#ifndef BLE_H
#define BLE_H

#include <zephyr/types.h>
#include <zephyr/device.h>
#include <zephyr/kernel.h>

#if defined(CONFIG_BT)
#include <zephyr/bluetooth/bluetooth.h>
#include <zephyr/drivers/uart.h>
#ifdef CONFIG_UART_ASYNC_ADAPTER
#include <uart_async_adapter.h>
#endif
#endif

#if defined(CONFIG_BT)
#if defined(CONFIG_BT_NUS_THREAD_STACK_SIZE)
#define BLE_NUS_STACK_SIZE CONFIG_BT_NUS_THREAD_STACK_SIZE
#else
#define BLE_NUS_STACK_SIZE 2048
#endif
#define STACKSIZE BLE_NUS_STACK_SIZE
#define PRIORITY 7
#define DEVICE_NAME CONFIG_BT_DEVICE_NAME
#define DEVICE_NAME_LEN (sizeof(DEVICE_NAME) - 1)
#if defined(CONFIG_BT_NUS_UART_BUFFER_SIZE)
#define BLE_NUS_UART_BUF_SIZE CONFIG_BT_NUS_UART_BUFFER_SIZE
#else
#define BLE_NUS_UART_BUF_SIZE 256
#endif
#define UART_BUF_SIZE BLE_NUS_UART_BUF_SIZE
#if defined(CONFIG_BT_NUS_UART_RX_WAIT_TIME)
#define UART_WAIT_FOR_RX CONFIG_BT_NUS_UART_RX_WAIT_TIME
#else
#define UART_WAIT_FOR_RX 50000
#endif
#else
#define STACKSIZE 256
#define PRIORITY 7
#define DEVICE_NAME "Chronos"
#define DEVICE_NAME_LEN (sizeof(DEVICE_NAME) - 1)
#define UART_BUF_SIZE 40
#define UART_WAIT_FOR_RX 50000
#endif

#define RUN_LED_BLINK_INTERVAL 1000

#define UART_WAIT_FOR_BUF_DELAY K_MSEC(50)

#if defined(CONFIG_BT)
#ifdef CONFIG_UART_ASYNC_ADAPTER
UART_ASYNC_ADAPTER_INST_DEFINE(async_adapter);
#else
#define async_adapter NULL
#endif
#include <dk_buttons_and_leds.h>
#define RUN_STATUS_LED DK_LED1
#define CON_STATUS_LED DK_LED2
#define KEY_PASSKEY_ACCEPT DK_BTN1_MSK
#define KEY_PASSKEY_REJECT DK_BTN2_MSK
#else
#define RUN_STATUS_LED 0
#define CON_STATUS_LED 0
#define KEY_PASSKEY_ACCEPT 0
#define KEY_PASSKEY_REJECT 0
#endif

extern struct k_sem ble_init_ok;
#if defined(CONFIG_BT)
struct bt_nus_cb;
extern struct bt_nus_cb nus_cb;
void ble_advertising_work_init(void);
extern struct k_work_delayable uart_work;
extern const struct device *uart;
void uart_work_handler(struct k_work *item);
bool uart_test_async_api(const struct device *dev);
void configure_gpio(void);
void error(void);
void uart_cb(const struct device *dev, struct uart_event *evt, void *user_data);
int uart_init(void);
#endif
void ble_write_thread(void);

#if defined(CONFIG_BT)
extern struct k_work adv_work;
extern struct bt_conn *current_conn;
extern struct bt_conn *auth_conn;
extern const struct bt_data ad[];
extern const struct bt_data sd[];
extern const size_t ad_len;
extern const size_t sd_len;
extern bool ble_data_ready;
void adv_work_handler(struct k_work *work);
void advertising_start(void);
void connected(struct bt_conn *conn, uint8_t err);
void disconnected(struct bt_conn *conn, uint8_t reason);
void recycled_cb(void);
void bt_receive_cb(struct bt_conn *conn, const uint8_t *const data, uint16_t len);
int ble_send_samples(int16_t *samples, size_t count);
#ifdef CONFIG_BT_NUS_SECURITY_ENABLED
void security_changed(struct bt_conn *conn, bt_security_t level,
		      enum bt_security_err err);
#endif

#if defined(CONFIG_BT_NUS_SECURITY_ENABLED)
void auth_passkey_display(struct bt_conn *conn, unsigned int passkey);
void auth_passkey_confirm(struct bt_conn *conn, unsigned int passkey);
void auth_cancel(struct bt_conn *conn);
void pairing_complete(struct bt_conn *conn, bool bonded);
void pairing_failed(struct bt_conn *conn, enum bt_security_err reason);
extern struct bt_conn_auth_cb conn_auth_callbacks;
extern struct bt_conn_auth_info_cb conn_auth_info_callbacks;
#else
extern struct bt_conn_auth_cb conn_auth_callbacks;
extern struct bt_conn_auth_info_cb conn_auth_info_callbacks;
#endif

#ifdef CONFIG_BT_NUS_SECURITY_ENABLED
void num_comp_reply(bool accept);
void button_changed(uint32_t button_state, uint32_t has_changed);
#endif
#endif /* CONFIG_BT */

struct uart_data_t {
	void *fifo_reserved;
	uint8_t data[UART_BUF_SIZE];
	uint16_t len;
};

#endif /* BLE_H */
```

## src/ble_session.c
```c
#if defined(CONFIG_BT)

#include "ble_session.h"
#include "BLE.h"

#include <zephyr/bluetooth/bluetooth.h>
#include <zephyr/bluetooth/hci.h>
#include <zephyr/bluetooth/conn.h>
#include <zephyr/device.h>
#include <zephyr/devicetree.h>
#include <zephyr/drivers/gpio.h>
#include <errno.h>
#include <zephyr/kernel.h>
#include <zephyr/logging/log.h>
#include <bluetooth/services/nus.h>
#include <zephyr/settings/settings.h>

LOG_MODULE_REGISTER(ble_session, LOG_LEVEL_INF);

/* P1.10 — reed switch (pull-up; short to GND when magnet present). */
#define REED_GPIO_NODE  DT_NODELABEL(gpio1)
#define REED_PIN        10

static const struct device *reed_port;
static struct gpio_callback reed_gpio_cb;
static struct k_work_delayable reed_debounce_work;
static struct k_work_delayable session_inactivity_work;

static bool session_active;
static bool ble_thread_released;
static bool nus_initialized;
static bool settings_have_loaded;

static void session_stop_internal(void);
static void inactivity_handler(struct k_work *work);
static void reed_debounce_handler(struct k_work *work);

void ble_session_feed_activity(void)
{
	if (session_active) {
		k_work_reschedule(&session_inactivity_work, K_MINUTES(5));
	}
}

static void inactivity_handler(struct k_work *work)
{
	ARG_UNUSED(work);
	if (session_active) {
		LOG_INF("BLE session: 5 min inactivity, stopping");
		session_stop_internal();
	}
}

static void session_stop_internal(void)
{
	int err;

	k_work_cancel_delayable(&reed_debounce_work);
	k_work_cancel_delayable(&session_inactivity_work);

	dk_set_led_off(RUN_STATUS_LED);

	err = bt_le_adv_stop();
	if (err && err != -EALREADY) {
		LOG_WRN("Adv stop err %d", err);
	}

	if (current_conn) {
		err = bt_conn_disconnect(current_conn, BT_HCI_ERR_REMOTE_USER_TERM_CONN);
		if (err && err != -ENOTCONN) {
			LOG_WRN("Disconnect err %d", err);
		}
	}

	err = bt_disable();
	if (err) {
		LOG_WRN("bt_disable err %d", err);
	}

	nus_initialized = false;
	session_active = false;
	LOG_INF("BLE session off");
}

static int session_start_internal(void)
{
	int err;

	if (session_active) {
		return 0;
	}

	err = bt_enable(NULL);
	if (err) {
		LOG_ERR("bt_enable failed: %d", err);
		return err;
	}

	if (IS_ENABLED(CONFIG_SETTINGS) && !settings_have_loaded) {
		settings_have_loaded = true;
		settings_load();
	}

	if (!nus_initialized) {
		err = bt_nus_init(&nus_cb);
		if (err) {
			LOG_ERR("bt_nus_init failed: %d", err);
			(void)bt_disable();
			return err;
		}
		nus_initialized = true;
	}

	if (!ble_thread_released) {
		k_sem_give(&ble_init_ok);
		ble_thread_released = true;
	}

	advertising_start();
	session_active = true;
	k_work_reschedule(&session_inactivity_work, K_MINUTES(5));
	dk_set_led_on(RUN_STATUS_LED);
	LOG_INF("BLE session on (advertising)");
	return 0;
}

static void reed_debounce_handler(struct k_work *work)
{
	ARG_UNUSED(work);

	if (!reed_port || !device_is_ready(reed_port)) {
		return;
	}

	if (session_active) {
		LOG_INF("Reed: closing BLE session");
		session_stop_internal();
	} else {
		LOG_INF("Reed: opening BLE session");
		(void)session_start_internal();
	}
}

static void reed_gpio_isr(const struct device *port, struct gpio_callback *cb,
			  uint32_t pins)
{
	ARG_UNUSED(port);
	ARG_UNUSED(cb);
	ARG_UNUSED(pins);
	k_work_reschedule(&reed_debounce_work, K_MSEC(50));
}

void ble_session_init(void)
{
	int err;

	reed_port = DEVICE_DT_GET(REED_GPIO_NODE);
	if (!device_is_ready(reed_port)) {
		LOG_ERR("GPIO1 not ready for reed (P1.10)");
		return;
	}

	err = gpio_pin_configure(reed_port, REED_PIN, GPIO_INPUT | GPIO_PULL_UP);
	if (err) {
		LOG_ERR("Reed pin cfg err %d", err);
		return;
	}

	err = gpio_pin_interrupt_configure(reed_port, REED_PIN, GPIO_INT_EDGE_BOTH);
	if (err) {
		LOG_ERR("Reed IRQ cfg err %d", err);
		return;
	}

	gpio_init_callback(&reed_gpio_cb, reed_gpio_isr, BIT(REED_PIN));
	gpio_add_callback(reed_port, &reed_gpio_cb);

	k_work_init_delayable(&reed_debounce_work, reed_debounce_handler);
	k_work_init_delayable(&session_inactivity_work, inactivity_handler);

	ble_advertising_work_init();

	dk_set_led_off(RUN_STATUS_LED);

	LOG_INF("Reed on P1.10: toggle to enable/disable BLE");
}

#endif /* CONFIG_BT */
```

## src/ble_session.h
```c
#ifndef BLE_SESSION_H
#define BLE_SESSION_H

#if defined(CONFIG_BT)

/** Magnetic reed on P1.10: debounced edges toggle BLE session on/off. */
void ble_session_init(void);

/** Reset 5-minute inactivity timeout (call on each NUS RX). */
void ble_session_feed_activity(void);

#else

static inline void ble_session_init(void) {}
static inline void ble_session_feed_activity(void) {}

#endif

#endif /* BLE_SESSION_H */
```

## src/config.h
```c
#ifndef CONFIG_H
#define CONFIG_H

#define MEASURE_TIMER 0 // 1: testing timer accuracy with built-in timer
                        // 0: disable measurement timer
#define SPI_VERBOSE 0   // 1: enable verbose SPI logging

/* CS hold delay: loops after nrfx_spim_xfer before cs_deselect (~2-3 us). Tune via scope:
 * Increase if CS rises before SCLK finishes; decrease if pulse is longer than needed.
 * At 64 MHz: ~32-64 = 2 us, ~64-96 = 3 us. */
#define SPI_CS_HOLD_DELAY_LOOPS  64

/* Biphasic square-wave stimulation (compile-time; overrides BLE) */
#define CONFIG_STIM_AMPLITUDE        0xFFAA   /* DAC amplitude (16-bit). Phase 2 = opposite. */
#define CONFIG_PULSE_WIDTH_US        200u      /* Pulse duration per phase (us). Typically 200 us. */
#define CONFIG_INTER_PHASE_GAP_US    10u       /* Gap between phase 1 and phase 2 (us). Typically 10 us.
                                                  Note: Actual gap is SWITCH_PERIOD in timer.h; timer not modified. */
#define CONFIG_STIM_FREQUENCY_HZ     130u      /* Biphasic pulse rate (Hz). Typically 130 Hz. */

#endif // CONFIG_H
```

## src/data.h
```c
#ifndef DATA_H
#define DATA_H
#include <zephyr/types.h>

typedef struct {
	uint16_t DAC_amplitude;
	uint16_t pulse_width;
	uint16_t frequency;
} stim_setting;

/** Byte 0 of NUS payload: explicit run/stop (separate from DAC code). */
#define STIM_CTRL_STOP  0x00u
#define STIM_CTRL_START 0x01u

/*byte 2 and 3 of NUS payload: explicit run/stop of recording*/
#define ADC_CTRL_START 0x02u
#define ADC_CTRL_STOP 0x03u
#define ADC_PACKET_LEN 1u
#define STIM_PACKET_LEN (1u + sizeof(stim_setting))

#define BLE_DATA_BUFFER_SIZE 32u

extern stim_setting settings;
extern stim_setting pending_settings;
extern uint8_t ble_received_data[];
extern uint16_t ble_data_length;

void data_init_defaults(void);
void process_received_data(stim_setting *settings, uint8_t *ble_received_data, uint16_t ble_data_length);

#endif /* DATA_H */
```

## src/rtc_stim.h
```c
#ifndef RTC_STIM_H
#define RTC_STIM_H

#include <stdint.h>

/** Start LFCLK (32.768 kHz). Optional; call before rtc_stim_init if needed. */
void rtc_stim_start_lfclk(void);

/**
 * Initialize stimulation period using TIMER2 (does not use TIMER0 or TIMER1).
 * Compare event fires every (1/frequency_hz) seconds. On each compare: HFCLK
 * is ensured, event0 (DAC1) runs, then TIMER0 one-shot runs for the biphasic phases.
 * @param frequency_hz Stimulation rate in Hz (e.g. 130).
 */
void rtc_stim_init(uint16_t frequency_hz);

#endif /* RTC_STIM_H */
```
